# SAM9X60D1G device description
Architecture: ARM926EJ-S; Family: SAM9; Series: SAM9X
Registers are 32-bit, read-write, no defined reset value unless marked. A register's access mark holds for its fields unless they carry their own. Offsets are from the block's base; [hi:lo] are bit positions; {n}, {i} and the like mark numbered series.

## OTPC — OTP Memory Controller
Instances: OTPC 0xEFF00000
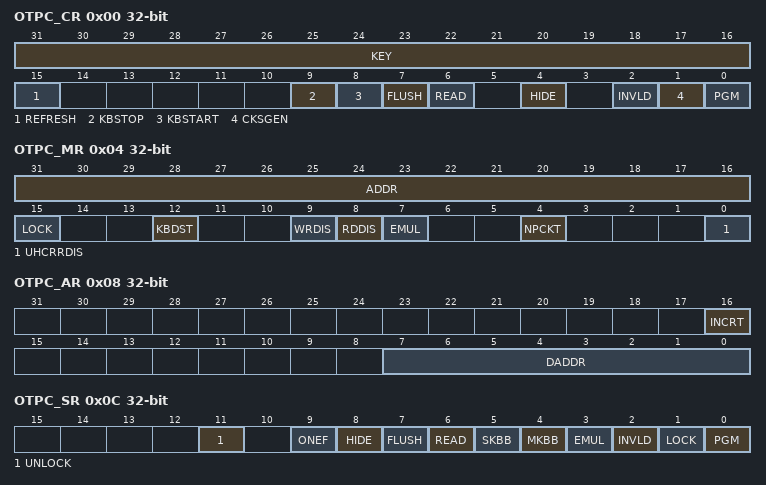
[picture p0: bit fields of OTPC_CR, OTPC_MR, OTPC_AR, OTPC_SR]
0x00 OTPC_CR wo — Control Register
  [31:16] KEY — Programming Key
  [15] REFRESH — Refresh the Area
  [9] KBSTOP — Key Bus Transfer Stop
  [8] KBSTART — Key Bus Transfer Start
  [7] FLUSH — Flush Temporary Registers
  [6] READ — Read Area
  [4] HIDE — Hide Packet
  [2] INVLD — Invalidate Packet
  [1] CKSGEN — Generate Checksum
  [0] PGM — Program Packet
0x04 OTPC_MR — Mode Register
  [31:16] ADDR — Address
  [15] LOCK
  [12] KBDST — Key Bus Destination
    0=TDES (The TDES is the destination of the key transfer.); 1=AES (The AES is the destination of the key transfer.)
  [9] WRDIS — Write Disable
  [8] RDDIS — Read Disable
  [7] EMUL — Emulation Enable
  [4] NPCKT — New Packet
  [0] UHCRRDIS — User Hardware Configuration Register Read Disable
0x08 OTPC_AR — Address Register
  [16] INCRT — Increment Type
    0=AFTER_READ (Increment DADDR after a read of OTPC_DR.); 1=AFTER_WRITE (Increment DADDR after a write of OTPC_DR.)
  [7:0] DADDR — Data Address
0x0C OTPC_SR ro — Status Register
  [11] UNLOCK — OTP Registers Unlocked
  [9] ONEF — One Found
  [8] HIDE — Hiding On-Going
  [7] FLUSH — Flush On-Going
  [6] READ — Read On-Going
  [5] SKBB — Slave Key Bus Busy
  [4] MKBB — Master Key Bus Busy
  [3] EMUL — Emulation Enabled
  [2] INVLD — Invalidation On-Going
  [1] LOCK — Lock On-Going
  [0] PGM — Programming On-Going
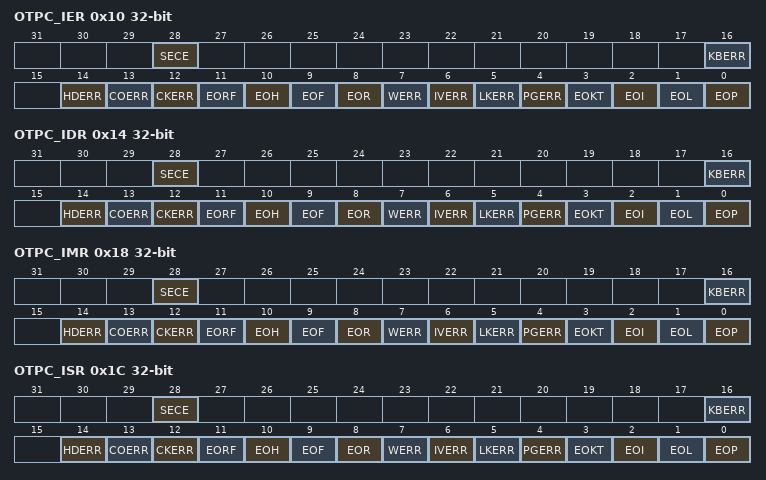
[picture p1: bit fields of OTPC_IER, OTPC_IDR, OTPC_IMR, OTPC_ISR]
0x10 OTPC_IER wo — Interrupt Enable Register
  [28] SECE — Security and/or Safety Event Interrupt Enable
  [16] KBERR — Key Bus Error Interrupt Enable
  [14] HDERR — Hide Error Interrupt Enable
  [13] COERR — Corruption Error Interrupt Enable
  [12] CKERR — Checksum Check Error Interrupt Enable
  [11] EORF — End Of Refresh Interrupt Enable
  [10] EOH — End Of Hide Interrupt Enable
  [9] EOF — End Of Flush Interrupt Enable
  [8] EOR — End Of Read Interrupt Enable
  [7] WERR — Write Error Interrupt Enable
  [6] IVERR — Invalidation Error Interrupt Enable
  [5] LKERR — Locking Error Interrupt Enable
  [4] PGERR — Programming Error Interrupt Enable
  [3] EOKT — End Of Key Transfer Interrupt Enable
  [2] EOI — End Of Invalidation Interrupt Enable
  [1] EOL — End Of Locking Interrupt Enable
  [0] EOP — End Of Programming Interrupt Enable
0x14 OTPC_IDR wo — Interrupt Disable Register
  [28] SECE — Security and/or Safety Event Interrupt Disable
  [16] KBERR — Key Bus Error Interrupt Disable
  [14] HDERR — Hide Error Interrupt Disable
  [13] COERR — Corruption Error Interrupt Disable
  [12] CKERR — Checksum Check Error Interrupt Disable
  [11] EORF — End Of Refresh Interrupt Disable
  [10] EOH — End Of Hide Interrupt Disable
  [9] EOF — End Of Flush Interrupt Disable
  [8] EOR — End Of Read Interrupt Disable
  [7] WERR — Write Error Interrupt Disable
  [6] IVERR — Invalidation Error Interrupt Disable
  [5] LKERR — Locking Error Interrupt Disable
  [4] PGERR — Programming Error Interrupt Disable
  [3] EOKT — End Of Key Transfer Interrupt Disable
  [2] EOI — End Of Invalidation Interrupt Disable
  [1] EOL — End Of Locking Interrupt Disable
  [0] EOP — End Of Programming Interrupt Disable
0x18 OTPC_IMR ro — Interrupt Mask Register
  [28] SECE — Security and/or Safety Event Interrupt Mask
  [16] KBERR — Key Bus Error Interrupt Mask
  [14] HDERR — Hide Error Interrupt Mask
  [13] COERR — Corruption Error Interrupt Mask
  [12] CKERR — Checksum Check Error Interrupt Mask
  [11] EORF — End Of Refresh Interrupt Mask
  [10] EOH — End Of Hide Interrupt Mask
  [9] EOF — End Of Flush Interrupt Mask
  [8] EOR — End Of Read Interrupt Mask
  [7] WERR — Write Error Interrupt Mask
  [6] IVERR — Invalidation Error Interrupt Mask
  [5] LKERR — Locking Error Interrupt Mask
  [4] PGERR — Programming Error Interrupt Mask
  [3] EOKT — End Of Key Transfer Interrupt Mask
  [2] EOI — End Of Invalidation Interrupt Mask
  [1] EOL — End Of Locking Interrupt Mask
  [0] EOP — End Of Programming Interrupt Mask
0x1C OTPC_ISR ro — Interrupt Status Register
  [28] SECE — Security and/or Safety Event (cleared on read)
  [16] KBERR — Key Bus Error (cleared on read)
  [14] HDERR — Hide Error (cleared on read)
  [13] COERR — Corruption Error (cleared on read)
  [12] CKERR — Checksum Check Error (cleared on read)
  [11] EORF — End Of Refresh (cleared on read)
  [10] EOH — End Of Hide (cleared on read)
  [9] EOF — End Of Flush (cleared on read)
  [8] EOR — End Of Read (cleared on read)
  [7] WERR — Write Error (cleared on read)
  [6] IVERR — Invalidation Error (cleared on read)
  [5] LKERR — Locking Error (cleared on read)
  [4] PGERR — Programming Error (cleared on read)
  [3] EOKT — End Of Key Transfer (cleared on read)
  [2] EOI — End Of Invalidation (cleared on read)
  [1] EOL — End Of Locking (cleared on read)
  [0] EOP — End Of Programming (cleared on read)
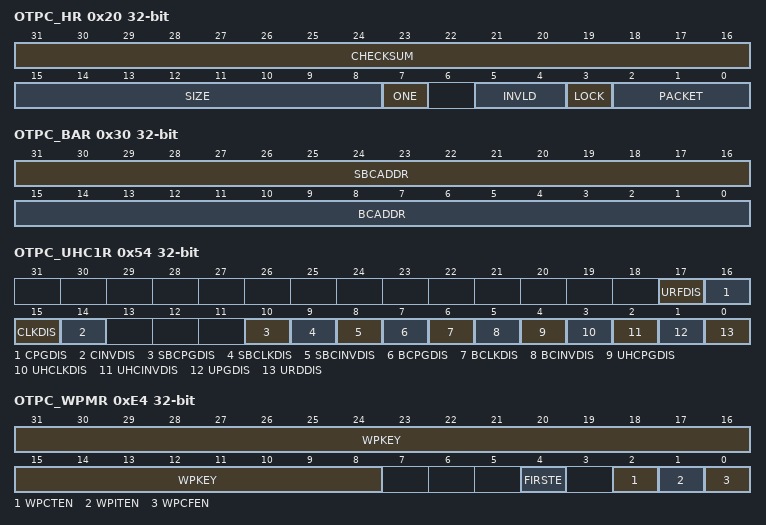
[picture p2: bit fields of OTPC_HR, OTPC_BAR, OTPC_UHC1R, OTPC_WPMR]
0x20 OTPC_HR — Header Register
  [31:16] CHECKSUM — Packet Checksum
  [15:8] SIZE — Packet Size
  [7] ONE
  [5:4] INVLD — Invalid Status
  [3] LOCK — Lock Status
  [2:0] PACKET — Packet Type
    1=REGULAR (Regular packet accessible through the User Interface); 2=KEY (Key packet accessible only through the Key Buses); 3=BOOT_CONFIGURATION (Boot Configuration packet); 4=SECURE_BOOT_CONFIGURATION (Secure Boot Configuration packet); 5=HARDWARE_CONFIGURATION (Hardware Configuration packet); 6=CUSTOM (Custom packet)
0x24 OTPC_DR — Data Register
  [31:0] DATA — Packet Data
0x30 OTPC_BAR ro — Boot Addresses Register
  [31:16] SBCADDR — Secure Boot Configuration Address
  [15:0] BCADDR — Boot Configuration Address
0x34 OTPC_CAR ro — Custom Address Register
  [15:0] CADDR — Custom Address
0x50 OTPC_UHC0R ro — User Hardware Configuration 0 Register
  [7:0] JTAGDIS — JTAG Disable
0x54 OTPC_UHC1R ro — User Hardware Configuration 1 Register
  [17] URFDIS — User Refresh Disable
  [16] CPGDIS — Custom Packet Program Disable
  [15] CLKDIS — Custom Packet Lock Disable
  [14] CINVDIS — Custom Packet Invalidation Disable
  [10] SBCPGDIS — Secure Boot Configuration Packet Program Disable
  [9] SBCLKDIS — Secure Boot Configuration Packet Lock Disable
  [8] SBCINVDIS — Secure Boot Configuration Packet Invalidation Disable
  [7] BCPGDIS — Boot Configuration Packet Program Disable
  [6] BCLKDIS — Boot Configuration Packet Lock Disable
  [5] BCINVDIS — Boot Configuration Packet Invalidation Disable
  [4] UHCPGDIS — User Hardware Configuration Packet Program Disable
  [3] UHCLKDIS — User Hardware Configuration Packet Lock Disable
  [2] UHCINVDIS — User Hardware Configuration Packet Invalidation Disable
  [1] UPGDIS — User programming Disable
  [0] URDDIS — User Read Disable
{0x60+4i} OTPC_UID{i}R ro (i=0..3) — Product UID x Register {i}
  [31:0] UID — Unique Product ID
0xE4 OTPC_WPMR — Write Protection Mode Register
  [31:8] WPKEY — Write Protection Key
    0x4F5450=PASSWD (Writing any other value in this field aborts the write operation. Always reads as 0.)
  [4] FIRSTE — First Error Report Enable
  [2] WPCTEN — Write Protection Control Enable
  [1] WPITEN — Write Protection Interrupt Enable
  [0] WPCFEN — Write Protection Configuration Enable
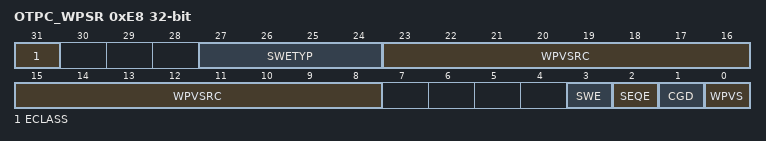
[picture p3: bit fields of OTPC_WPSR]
0xE8 OTPC_WPSR ro — Write Protection Status Register
  [31] ECLASS — Software Error Class
    0=WARNING (An abnormal access that does not have any impact.); 1=ERROR (An abnormal access that may have an impact.)
  [27:24] SWETYP — Software Error Type
    0=READ_WO (A write-only register has been read (warning).); 1=WRITE_RO (A write access has been performed on a read-only register (warning).); 2=CONF_CHG (A change has been made into the configuration (error).); 3=KEY_ERROR (A write has been computed in OTPC_CR or OTPC_WPMR register with a wrong value in the related KEY field (error).)
  [23:8] WPVSRC — Write Protection Violation Source
  [3] SWE — Software Control Error (cleared on read)
  [2] SEQE — Internal Sequencer Error (cleared on read)
  [1] CGD — Clock Glitch Detected (cleared on read)
  [0] WPVS — Write Protection Violation Status (cleared on read)

## Notices in the file
Copyright (c) 2019 Microchip Technology Inc.
SPDX-License-Identifier: Apache-2.0
Licensed under the Apache License, Version 2.0 (the "License");
you may not use this file except in compliance with the License.
You may obtain a copy of the License at
http://www.apache.org/licenses/LICENSE-2.0
Unless required by applicable law or agreed to in writing, software
distributed under the License is distributed on an "AS IS" BASIS,
WITHOUT WARRANTIES OR CONDITIONS OF ANY KIND, either express or implied.
See the License for the specific language governing permissions and
limitations under the License.
